# LPC15xx register map
File version: 0.7
CPU: CM3 r2p1, little endian, no MPU, no FPU, 3 interrupt priority bits
Registers are 32-bit, read-write, reset 0x0 unless marked. A register's access mark holds for its fields unless they carry their own. Offsets are from the block's base; [hi:lo] are bit positions; {n}, {i} and the like mark numbered series; 'fields as' and 'values as' point back to an identical list.

## ACMP — Analog comparators ACMP0/1/2/3
Base 0x40008000
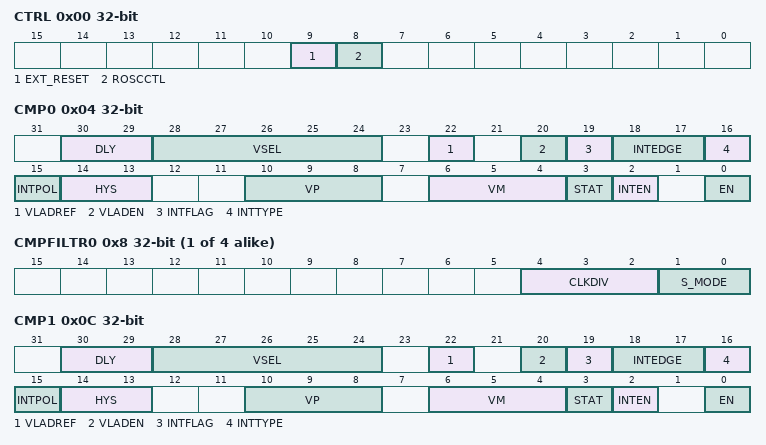
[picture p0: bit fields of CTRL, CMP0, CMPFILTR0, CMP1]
0x00 CTRL — Comparator block control register
  [9] EXT_RESET — Selects the reset source for the ROSC output.
    0=INTERNAL (Internal. The ROSC output is reset by the internal chip reset.); 1=FROM_PIN_ROSC_RESET (From pin ROSC_RESET. The ROSC output is reset by the ROSC_RESET input.)
  [8] ROSCCTL — Selects the which comparators set and reset the ROSC output.
    0=ACMP1_ACMP0 (ACMP1/ACMP0. The ROSC output is set by ACMP1 and reset by ACMP0.); 1=ACMP0_ACMP1 (ACMP0/ACMP1. The ROSC output is set by ACMP0 and reset by ACMP1.)
0x04 CMP0 — Comparator 0 source control
  [30:29] DLY — Configure the propagation delay. A shorter propagation delay means higher power consumption. Use values from 0x0 (shortest propagation delay and highest power consumption) to 0x2 (longest propagation delay and lowest power consumption). See the data sheet for details.
  [28:24] VSEL — Voltage ladder value for comparator 0. The reference voltage Vref depends on the setting of VLADREF (either VDD(3V3) or voltage on pin VREF_CMP). 00000 = Vss. 00001 = 1 x Vref / 31. 00010 = 2 x Vref / 31. ... 11111 = Vref
  [22] VLADREF — Voltage reference select for comparator 0 voltage ladder.
    0=VREF_CMP_PIN; 1=VDDA_PIN
  [20] VLADEN — Voltage ladder enable for comparator 0.
    0=DISABLED (Disabled. The Comparator voltage ladder is disabled.); 1=ENABLED (Enabled. The Comparator voltage ladder is enabled.)
  [19] INTFLAG — Interrupt flag.
    0=NOT_PENDING (Not pending. The Comparator interrupt is not pending.); 1=PENDING (Pending. The Comparator interrupt is pending. Writing a 1 to this bit clears the flag.)
  [18:17] INTEDGE — Select edge triggered interrupt to be active on either high or low transitions, when INTTYPE = 0.
    0=FALLING (Falling. Comparator interrupt is active on falling edges.); 1=RISING (Rising. Comparator interrupt is active on rising edges.); 2=BOTH_EDGES (Both edges. Comparator Interrupt is active on both edges.)
  [16] INTTYPE — Select interrupt type.
    0=EDGE (Edge. Comparator interrupt is edge triggered.); 1=LEVEL (Level. Comparator interrupt is level triggered.)
  [15] INTPOL — Selects the polarity of the CMP output for purposes of generating level interrupts.
    0=NOT_INVERTED (Not inverted. The output is used as-is for generating interrupts.); 1=INVERTED (Inverted. The output is used inverted for generating interrupts.)
  [14:13] HYS — Hysteresis control. When enabled, hysteresis determines the difference required between the comparator inputs before the comparator output switches. The difference must be in the direction opposite of the current comparator output.
    0=HYSTERESIS_IS_TURNED (Hysteresis is turned off, comparator output will change as the input voltages cross.); 1=HYSTERESIS_EQ_5_MV (Hysteresis = 5 mV.); 2=HYSTERESIS_EQ_10_MV (Hysteresis = 10 mV.); 3=HYSTERESIS_EQ_15_MV (Hysteresis = 15 mV.)
  [10:8] VP — VP input select.
    0=VREF_DIVIDER_0; 1=ACMP_I1; 2=ACMP_I2; 3=ACMP0_I3; 4=ACMP0_I4; 5=INTERNAL_0 (Internal 0.9 V band gap reference.); 6=TEMP_SENSOR; 7=ADC0_2 (ADC0_2. Input for ADC0 channel 2.)
  [6:4] VM — VM input select.
    values as VP
  [3] STAT — Comparator status. This bit reflects the comparator output
  [2] INTEN — Interrupt enable.
    0=DISABLED (Disabled. Interrupts are disabled..); 1=ENABLED (Enabled. Interrupts are enabled.. Must set to 1 for interrupts to propagate to the NVIC and start-up logic.)
  [0] EN — Comparator enable control.
    0=DISABLED (Disabled. Comparator disabled.); 1=ENABLED (Enabled. Comparator is enabled.)
{0x8+8i} CMPFILTR{i} (i=0..3) — Comparator 0 pin filter set-up
  [4:2] CLKDIV — Select clock divider for comparator clock CMP_PCLK.
    0=CMP_PCLK; 1=CMP_PCLKDIV2 (CMP_PCLK/2.); 2=CMP_PCLKDIV4 (CMP_PCLK/4.); 3=CMP_PCLKDIV8 (CMP_PCLK/8.); 4=CMP_PCLKDIV16 (CMP_PCLK/16.); 5=CMP_PCLKDIV32 (CMP_PCLK/32.); 6=CMP_PCLKDIV64 (CMP_PCLK/64.)
  [1:0] S_MODE — Digital filter sample mode.
    0=BYPASS_INPUT_FILTER; 1=1_CLOCK_CYCLE (1 clock cycle. Input pulses shorter than one filter clock are rejected.); 2=2_CLOCK_CYCLES (2 clock cycles. Input pulses shorter than two filter clocks are rejected.); 3=3_CLOCK_CYCLES (3 clock cycles. Input pulses shorter than three filter clocks are rejected.)
0x0C CMP1 — Comparator 1 source control
  [30:29] DLY — Configure the propagation delay. A shorter propagation delay means higher power consumption. Use values from 0x0 (shortest propagation delay and highest power consumption) to 0x2 (longest propagation delay and lowest power consumption). See the data sheet for details.
  [28:24] VSEL — Voltage ladder value for comparator 1. The reference voltage Vref depends on the setting of VLADREF (either VDD(3V3) or voltage on pin VREF_CMP). 00000 = Vss. 00001 = 1 x Vref / 31. 00010 = 2 x Vref / 31. ... 11111 = Vref
  [22] VLADREF — Voltage reference select for comparator 1 voltage ladder.
    0=VREF_CMP_PIN; 1=VDDA_PIN
  [20] VLADEN — Voltage ladder enable for comparator 1.
    values as CMP0.VLADEN
  [19] INTFLAG — Interrupt flag.
    values as CMP0.INTFLAG
  [18:17] INTEDGE — Select edge triggered interrupt to be active on either high or low transitions, when INTTYPE = 0.
    values as CMP0.INTEDGE
  [16] INTTYPE — Select interrupt type.
    values as CMP0.INTTYPE
  [15] INTPOL — Selects the polarity of the CMP output for purposes of generating level interrupts.
    values as CMP0.INTPOL
  [14:13] HYS — Hysteresis control. When enabled, hysteresis determines the difference required between the comparator inputs before the comparator output switches. The difference must be in the direction opposite of the current comparator output.
    values as CMP0.HYS
  [10:8] VP — VP input select.
    0=VREF_DIVIDER_1; 1=ACMP_I1; 2=ACMP_I2; 3=ACMP1_I3; 4=ACMP1_I4; 5=INTERNAL_0 (Internal 0.9 V band gap reference.); 6=ADC0_1 (ADC0_1. Input for ADC0 channel 1.); 7=ADC0_3 (ADC0_3. Input for ADC0 channel 3.)
  [6:4] VM — VM input select.
    values as VP
  [3] STAT — Comparator status. This bit reflects the comparator output
  [2] INTEN — Interrupt enable.
    values as CMP0.INTEN
  [0] EN — Comparator enable control.
    values as CMP0.EN
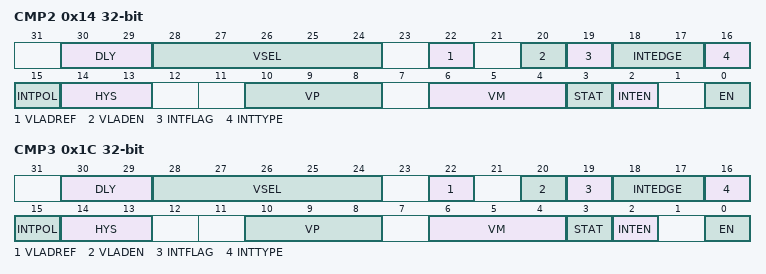
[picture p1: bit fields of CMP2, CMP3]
0x14 CMP2 — Comparator 2 source control
  [30:29] DLY — Configure the propagation delay. A shorter propagation delay means higher power consumption. Use values from 0x0 (shortest propagation delay and highest power consumption) to 0x2 (longest propagation delay and lowest power consumption). See the data sheet for details.
  [28:24] VSEL — Voltage ladder value for comparator 2. The reference voltage Vref depends on the setting of VLADREF (either VDD(3V3) or voltage on pin VREF_CMP). 00000 = Vss. 00001 = 1 x Vref / 31. 00010 = 2 x Vref / 31. ... 11111 = Vref
  [22] VLADREF — Voltage reference select for comparator 2 voltage ladder.
    0=VREF_CMP_PIN; 1=VDDA_PIN
  [20] VLADEN — Voltage ladder enable for comparator 2.
    values as CMP0.VLADEN
  [19] INTFLAG — Interrupt flag.
    values as CMP0.INTFLAG
  [18:17] INTEDGE — Select edge triggered interrupt to be active on either high or low transitions, when INTTYPE = 0.
    values as CMP0.INTEDGE
  [16] INTTYPE — Select interrupt type.
    values as CMP0.INTTYPE
  [15] INTPOL — Selects the polarity of the CMP output for purposes of generating level interrupts.
    values as CMP0.INTPOL
  [14:13] HYS — Hysteresis control. When enabled, hysteresis determines the difference required between the comparator inputs before the comparator output switches. The difference must be in the direction opposite of the current comparator output.
    values as CMP0.HYS
  [10:8] VP — VP input select.
    0=VREF_DIVIDER_2; 1=ACMP_I1; 2=ACMP_I2; 3=ACMP2_I3; 4=ACMP2_I4; 5=INTERNAL_0 (Internal 0.9 V band gap reference.); 6=ADC0_0 (ADC0_0. Input for ADC0 channel 0.); 7=ADC1_2 (ADC1_2. Input for ADC1 channel 2.)
  [6:4] VM — VM input select.
    values as VP
  [3] STAT — Comparator status. This bit reflects the comparator output
  [2] INTEN — Interrupt enable.
    values as CMP0.INTEN
  [0] EN — Comparator enable control.
    values as CMP0.EN
0x1C CMP3 — Comparator 3 source control
  [30:29] DLY — Configure the propagation delay. A shorter propagation delay means higher power consumption. Use values from 0x0 (shortest propagation delay and highest power consumption) to 0x2 (longest propagation delay and lowest power consumption). See the data sheet for details.
  [28:24] VSEL — Voltage ladder value for comparator 3. The reference voltage Vref depends on the setting of VLADREF (either VDD(3V3) or voltage on pin VREF_CMP). 00000 = Vss. 00001 = 1 x Vref / 31. 00010 = 2 x Vref / 31. ... 11111 = Vref
  [22] VLADREF — Voltage reference select for comparator 3 voltage ladder.
    0=VREF_CMP_PIN; 1=VDDA_PIN
  [20] VLADEN — Voltage ladder enable for comparator 3.
    values as CMP0.VLADEN
  [19] INTFLAG — Interrupt flag.
    values as CMP0.INTFLAG
  [18:17] INTEDGE — Select edge triggered interrupt to be active on either high or low transitions, when INTTYPE = 0.
    values as CMP0.INTEDGE
  [16] INTTYPE — Select interrupt type.
    values as CMP0.INTTYPE
  [15] INTPOL — Selects the polarity of the CMP output for purposes of generating level interrupts.
    values as CMP0.INTPOL
  [14:13] HYS — Hysteresis control. When enabled, hysteresis determines the difference required between the comparator inputs before the comparator output switches. The difference must be in the direction opposite of the current comparator output.
    values as CMP0.HYS
  [10:8] VP — VP input select.
    0=VREF_DIVIDER_3; 1=ACMP_I1; 2=ACMP_I2; 3=ACMP3_I3; 4=ACMP3_I4; 5=INTERNAL_0 (Internal 0.9 V band gap reference.); 6=ADC1_1 (ADC1_1. Input for ADC1 channel 1.); 7=ADC1_3 (ADC1_3. Input for ADC1 channel 3.)
  [6:4] VM — VM input select.
    values as VP
  [3] STAT — Comparator status. This bit reflects the comparator output
  [2] INTEN — Interrupt enable.
    values as CMP0.INTEN
  [0] EN — Comparator enable control.
    values as CMP0.EN
